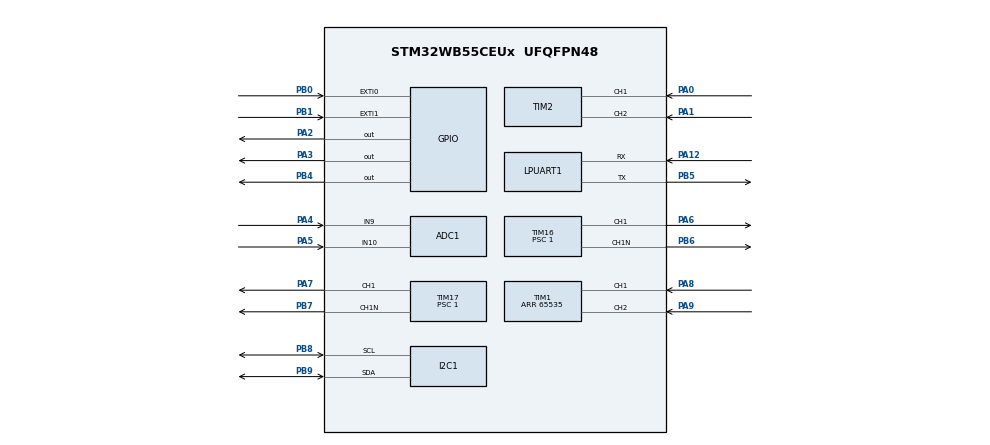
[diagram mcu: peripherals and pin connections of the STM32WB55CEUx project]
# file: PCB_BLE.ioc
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ADC1.Channel-0\#ChannelRegularConversion=ADC_CHANNEL_9
ADC1.Channel-1\#ChannelRegularConversion=ADC_CHANNEL_10
ADC1.ContinuousConvMode=ENABLE
ADC1.DMAContinuousRequests=ENABLE
ADC1.NbrOfConversion=2
ADC1.NbrOfConversionFlag=1
ADC1.OffsetNumber-0\#ChannelRegularConversion=ADC_OFFSET_NONE
ADC1.OffsetNumber-1\#ChannelRegularConversion=ADC_OFFSET_NONE
ADC1.Rank-0\#ChannelRegularConversion=1
ADC1.Rank-1\#ChannelRegularConversion=2
ADC1.SamplingTime-0\#ChannelRegularConversion=ADC_SAMPLETIME_640CYCLES_5
ADC1.SamplingTime-1\#ChannelRegularConversion=ADC_SAMPLETIME_640CYCLES_5
ADC1.master=1
Dma.ADC1.0.Direction=DMA_PERIPH_TO_MEMORY
Dma.ADC1.0.EventEnable=DISABLE
Dma.ADC1.0.Instance=DMA1_Channel1
Dma.ADC1.0.MemDataAlignment=DMA_MDATAALIGN_HALFWORD
Dma.ADC1.0.MemInc=DMA_MINC_ENABLE
Dma.ADC1.0.Mode=DMA_CIRCULAR
Dma.ADC1.0.PeriphDataAlignment=DMA_PDATAALIGN_HALFWORD
Dma.ADC1.0.PeriphInc=DMA_PINC_DISABLE
Dma.ADC1.0.Polarity=HAL_DMAMUX_REQ_GEN_RISING
Dma.ADC1.0.Priority=DMA_PRIORITY_LOW
Dma.ADC1.0.RequestNumber=1
Dma.ADC1.0.SignalID=NONE
Dma.ADC1.0.SyncEnable=DISABLE
Dma.ADC1.0.SyncPolarity=HAL_DMAMUX_SYNC_NO_EVENT
Dma.ADC1.0.SyncRequestNumber=1
Dma.ADC1.0.SyncSignalID=NONE
Dma.Request0=ADC1
FREERTOS.Tasks01=defaultTask,24,128,StartDefaultTask,Default,NULL,Dynamic,NULL,NULL
FREERTOS.configTOTAL_HEAP_SIZE=20000
FREERTOS.configUSE_NEWLIB_REENTRANT=1
I2C1.Timing=0x00B07CB4
LPTIM1.ClockPrescaler=LPTIM_PRESCALER_DIV128
Mcu.Family=STM32WB
Mcu.Name=STM32WB55CEUx
Mcu.Package=UFQFPN48
NVIC.ADC1_IRQn=true\:5\:0\:false\:false\:true\:true\:true\:true\:true
NVIC.DMA1_Channel1_IRQn=true\:5\:0\:false\:false\:true\:true\:false\:true\:true
NVIC.EXTI0_IRQn=true\:5\:0\:false\:false\:true\:true\:true\:true\:true
NVIC.HSEM_IRQn=true\:5\:0\:false\:false\:true\:true\:false\:true\:true
NVIC.IPCC_C1_RX_IRQn=true\:5\:0\:false\:false\:true\:true\:true\:true\:true
NVIC.IPCC_C1_TX_IRQn=true\:5\:0\:false\:false\:true\:true\:true\:true\:true
NVIC.LPTIM1_IRQn=true\:5\:0\:false\:false\:true\:true\:true\:true\:true
NVIC.PriorityGroup=NVIC_PRIORITYGROUP_4
NVIC.RTC_WKUP_IRQn=true\:5\:0\:false\:false\:true\:true\:true\:true\:true
OSC_IN.Mode=HSE-External-Oscillator
OSC_IN.Signal=RCC_OSC_IN
OSC_OUT.Mode=HSE-External-Oscillator
OSC_OUT.Signal=RCC_OSC_OUT
PA0.Signal=S_TIM2_CH1
PA1.Signal=S_TIM2_CH2
PA12.Mode=Asynchronous
PA12.Signal=LPUART1_RX
PA13.Mode=Serial_Wire
PA13.Signal=SYS_JTMS-SWDIO
PA14.Mode=Serial_Wire
PA14.Signal=SYS_JTCK-SWCLK
PA2.Signal=GPIO_Output
PA3.Signal=GPIO_Output
PA4.Signal=ADCx_IN9
PA5.Signal=ADCx_IN10
PA6.Signal=S_TIM16_CH1
PA7.Signal=S_TIM17_CH1
PA8.Signal=S_TIM1_CH1
PA9.Signal=S_TIM1_CH2
PB0.Signal=GPXTI0
PB1.Signal=GPXTI1
PB3.Signal=SYS_JTDO-SWO
PB4.Signal=GPIO_Output
PB5.Mode=Asynchronous
PB5.Signal=LPUART1_TX
PB6.Mode=PWM Generation1 CH1 CH1N
PB6.Signal=TIM16_CH1N
PB7.Mode=PWM Generation1 CH1 CH1N
PB7.Signal=TIM17_CH1N
PB8.Mode=I2C
PB8.Signal=I2C1_SCL
PB9.Mode=I2C
PB9.Signal=I2C1_SDA
PC14-OSC32_IN.Mode=LSE-External-Oscillator
PC14-OSC32_IN.Signal=RCC_OSC32_IN
PC15-OSC32_OUT.Mode=LSE-External-Oscillator
PC15-OSC32_OUT.Signal=RCC_OSC32_OUT
ProjectManager.HeapSize=0x200
ProjectManager.StackSize=0x400
ProjectManager.TargetToolchain=STM32CubeIDE
RCC.ADCFreq_Value=48000000
RCC.AHBFreq_Value=32000000
RCC.APB1Freq_Value=32000000
RCC.APB1TimFreq_Value=32000000
RCC.APB2Freq_Value=32000000
RCC.APB2TimFreq_Value=32000000
RCC.APB3Freq_Value=16000000
RCC.CortexFreq_Value=32000000
RCC.HCLKFreq_Value=32000000
RCC.HSE_VALUE=32000000
RCC.HSI48_VALUE=48000000
RCC.HSI_VALUE=16000000
RCC.PLLN=24
RCC.PLLR=RCC_PLLR_DIV3
RCC.PLLSAI1N=24
RCC.SYSCLKFreq_VALUE=32000000
RCC.SYSCLKSource=RCC_SYSCLKSOURCE_PLLCLK
RCC.USBFreq_Value=48000000
RCC.VCOOutputFreq_Value=96000000
RF1.Mode=RF1_Activate
RF1.Signal=RF_RF1
SH.ADCx_IN10.0=ADC1_IN10,IN10-Single-Ended
SH.ADCx_IN9.0=ADC1_IN9,IN9-Single-Ended
SH.S_TIM16_CH1.0=TIM16_CH1,PWM Generation1 CH1 CH1N
SH.S_TIM17_CH1.0=TIM17_CH1,PWM Generation1 CH1 CH1N
SH.S_TIM1_CH1.0=TIM1_CH1,Encoder_Interface
SH.S_TIM1_CH2.0=TIM1_CH2,Encoder_Interface
SH.S_TIM2_CH1.0=TIM2_CH1,Encoder_Interface
SH.S_TIM2_CH2.0=TIM2_CH2,Encoder_Interface
STM32_WPAN.BLE_DBG_APP_EN=1
STM32_WPAN.BLE_DBG_DIS_EN=1
STM32_WPAN.BLE_DBG_HRS_EN=1
STM32_WPAN.BLE_DBG_SVCCTL_EN=1
TIM1.AutoReloadPreload=TIM_AUTORELOAD_PRELOAD_ENABLE
TIM1.EncoderMode=TIM_ENCODERMODE_TI12
TIM1.IC1Filter=10
TIM1.Period=65535
TIM16.Channel=TIM_CHANNEL_1
TIM16.Period=1000-1
TIM16.Prescaler=1
TIM16.Pulse=0
TIM17.Channel=TIM_CHANNEL_1
TIM17.Period=1000-1
TIM17.Prescaler=1
TIM2.EncoderMode=TIM_ENCODERMODE_TI12
VP_FREERTOS_VS_CMSIS_V2.Mode=CMSIS_V2
VP_HSEM_VS_HSEM.Mode=HSEM_Activate
VP_IPCC_VS_IPCC.Mode=IPCC_Activate
VP_LPTIM1_VS_LPTIM_counterModeInternalClock.Mode=Counts__internal_clock_event_00
VP_MEMORYMAP_VS_MEMORYMAP.Mode=CurAppReg
VP_RTC_VS_RTC_Activate.Mode=RTC_Enabled
VP_RTC_VS_RTC_WakeUp_intern.Mode=WakeUp
VP_STM32_WPAN_VS_BLE_HOST.Mode=STM32_WPAN_Enabled
VP_TIM16_VS_ClockSourceINT.Mode=Enable_Timer
VP_TIM17_VS_ClockSourceINT.Mode=Enable_Timer
VP_TINY_LPM_VS_TINY_LPM.Mode=TINY_LPM_Enabled
board=custom

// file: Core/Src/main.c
/* USER CODE BEGIN Header */
/**
 ******************************************************************************
 * @file : main.c
 * @brief : Main program body
 ******************************************************************************
 */
/* USER CODE END Header */
#include "main.h"
#include "cmsis_os.h"
#include "adc.h"
#include "dma.h"
#include "i2c.h"
#include "ipcc.h"
#include "lptim.h"
#include "usart.h"
#include "rf.h"
#include "rtc.h"
#include "tim.h"
#include "gpio.h"

/* USER CODE BEGIN Includes */
#include "app.h"
/* USER CODE END Includes */

/* USER CODE BEGIN PV */

/* Variables partagées */

/* USER CODE END PV */

void SystemClock_Config(void);
void PeriphCommonClock_Config(void);
void MX_FREERTOS_Init(void);

int main(void)
{

  /* MCU Configuration--------------------------------------------------------*/

  /* Reset of all peripherals, Initializes the Flash interface and the Systick. */
  HAL_Init();
  /* Config code for STM32_WPAN (HSE Tuning must be done before system clock configuration) */
  MX_APPE_Config();

  /* Configure the system clock */
  SystemClock_Config();

  /* Configure the peripherals common clocks */
  PeriphCommonClock_Config();

  /* IPCC initialisation */
  MX_IPCC_Init();

  /* USER CODE BEGIN SysInit */
	/* Reset du CPU2 (coprocesseur BLE) */
//	__HAL_RCC_HSEM_CLK_ENABLE();
//	HAL_HSEM_ActivateNotification(__HAL_HSEM_SEMID_TO_MASK(HSEM_ID_IPCC_INIT));
//
//	/* Lancement du firmware sans fil sur CPU2 */
//	APPE_SysStatus_Notification(SHCI_C2_Reinit());

  /* USER CODE END SysInit */

  /* Initialize all configured peripherals */
  MX_GPIO_Init();
  MX_DMA_Init();
  MX_ADC1_Init();
  MX_LPTIM1_Init();
  MX_RTC_Init();
  MX_TIM1_Init();
  MX_TIM2_Init();
  MX_TIM16_Init();
  MX_TIM17_Init();
  MX_I2C1_Init();
  MX_LPUART1_UART_Init();
  MX_RF_Init();
  /* USER CODE BEGIN 2 */
	osKernelInitialize();

	app_init();

	app_task_init();
  /* USER CODE END 2 */

  /* Init scheduler */
  osKernelInitialize();
  /* Init code for STM32_WPAN */
  MX_APPE_Init();
  /* Call init function for freertos objects (in cmsis_os2.c) */
  MX_FREERTOS_Init();

  /* Start scheduler */
  osKernelStart();

  /* We should never get here as control is now taken by the scheduler */

  /* Infinite loop */
	while (1)
	{

	}
}

void SystemClock_Config(void)
{
  RCC_OscInitTypeDef RCC_OscInitStruct = {0};
  RCC_ClkInitTypeDef RCC_ClkInitStruct = {0};

  /** Configure the main internal regulator output voltage
  */
  __HAL_PWR_VOLTAGESCALING_CONFIG(PWR_REGULATOR_VOLTAGE_SCALE1);

  /** Initializes the RCC Oscillators according to the specified parameters
  * in the RCC_OscInitTypeDef structure.
  */
  RCC_OscInitStruct.OscillatorType = RCC_OSCILLATORTYPE_HSI|RCC_OSCILLATORTYPE_LSI1
                              |RCC_OSCILLATORTYPE_HSE|RCC_OSCILLATORTYPE_MSI;
  RCC_OscInitStruct.HSEState = RCC_HSE_ON;
  RCC_OscInitStruct.HSIState = RCC_HSI_ON;
  RCC_OscInitStruct.MSIState = RCC_MSI_ON;
  RCC_OscInitStruct.HSICalibrationValue = RCC_HSICALIBRATION_DEFAULT;
  RCC_OscInitStruct.MSICalibrationValue = RCC_MSICALIBRATION_DEFAULT;
  RCC_OscInitStruct.MSIClockRange = RCC_MSIRANGE_6;
  RCC_OscInitStruct.LSIState = RCC_LSI_ON;
  RCC_OscInitStruct.PLL.PLLState = RCC_PLL_ON;
  RCC_OscInitStruct.PLL.PLLSource = RCC_PLLSOURCE_MSI;
  RCC_OscInitStruct.PLL.PLLM = RCC_PLLM_DIV1;
  RCC_OscInitStruct.PLL.PLLN = 24;
  RCC_OscInitStruct.PLL.PLLP = RCC_PLLP_DIV2;
  RCC_OscInitStruct.PLL.PLLR = RCC_PLLR_DIV3;
  RCC_OscInitStruct.PLL.PLLQ = RCC_PLLQ_DIV2;
  if (HAL_RCC_OscConfig(&RCC_OscInitStruct) != HAL_OK)
  {
    Error_Handler();
  }

  /** Configure the SYSCLKSource, HCLK, PCLK1 and PCLK2 clocks dividers
  */
  RCC_ClkInitStruct.ClockType = RCC_CLOCKTYPE_HCLK4|RCC_CLOCKTYPE_HCLK2
                              |RCC_CLOCKTYPE_HCLK|RCC_CLOCKTYPE_SYSCLK
                              |RCC_CLOCKTYPE_PCLK1|RCC_CLOCKTYPE_PCLK2;
  RCC_ClkInitStruct.SYSCLKSource = RCC_SYSCLKSOURCE_PLLCLK;
  RCC_ClkInitStruct.AHBCLKDivider = RCC_SYSCLK_DIV1;
  RCC_ClkInitStruct.APB1CLKDivider = RCC_HCLK_DIV1;
  RCC_ClkInitStruct.APB2CLKDivider = RCC_HCLK_DIV1;
  RCC_ClkInitStruct.AHBCLK2Divider = RCC_SYSCLK_DIV1;
  RCC_ClkInitStruct.AHBCLK4Divider = RCC_SYSCLK_DIV1;

  if (HAL_RCC_ClockConfig(&RCC_ClkInitStruct, FLASH_LATENCY_1) != HAL_OK)
  {
    Error_Handler();
  }
}

void PeriphCommonClock_Config(void)
{
  RCC_PeriphCLKInitTypeDef PeriphClkInitStruct = {0};

  /** Initializes the peripherals clock
  */
  PeriphClkInitStruct.PeriphClockSelection = RCC_PERIPHCLK_SMPS|RCC_PERIPHCLK_RFWAKEUP;
  PeriphClkInitStruct.RFWakeUpClockSelection = RCC_RFWKPCLKSOURCE_HSE_DIV1024;
  PeriphClkInitStruct.SmpsClockSelection = RCC_SMPSCLKSOURCE_HSI;
  PeriphClkInitStruct.SmpsDivSelection = RCC_SMPSCLKDIV_RANGE1;

  if (HAL_RCCEx_PeriphCLKConfig(&PeriphClkInitStruct) != HAL_OK)
  {
    Error_Handler();
  }
}

/* USER CODE BEGIN 4 */
/* Callback ADC */

/* USER CODE END 4 */

void Error_Handler(void)
{
	__disable_irq();
	while (1)
	{
	}
}
